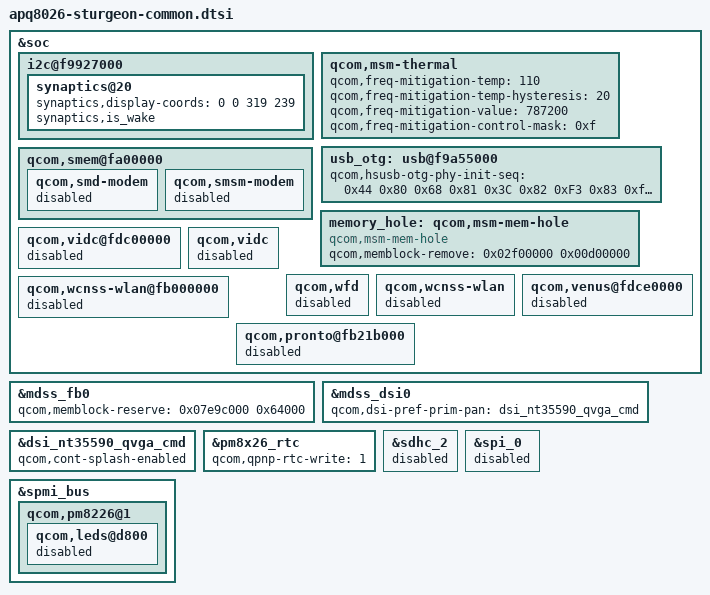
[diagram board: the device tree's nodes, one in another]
/* Copyright (c) 2015, HUAWEI TECHNOLOGIES CO., LTD. All rights reserved.
 *
 * This program is free software; you can redistribute it and/or modify
 * it under the terms of the GNU General Public License version 2 and
 * only version 2 as published by the Free Software Foundation.
 *
 * This program is distributed in the hope that it will be useful,
 * but WITHOUT ANY WARRANTY; without even the implied warranty of
 * MERCHANTABILITY or FITNESS FOR A PARTICULAR PURPOSE.  See the
 * GNU General Public License for more details.
 */

&soc {
	i2c@f9927000 { /* BLSP1 QUP5 */
		synaptics@20 {
			synaptics,display-coords = <0 0 319 239>;
		};
	};

	qcom,msm-thermal {
		qcom,freq-mitigation-temp = <110>;
		qcom,freq-mitigation-temp-hysteresis = <20>;
		qcom,freq-mitigation-value = <787200>;
		qcom,freq-mitigation-control-mask = <0xf>;
	};
	usb_otg: usb@f9a55000 {
		qcom,hsusb-otg-phy-init-seq =
			<0x44 0x80 0x68 0x81 0x3C 0x82 0xF3 0x83 0xffffffff>;
		/delete-property/ qcom,hsusb-otg-disable-reset;
	};
};

&mdss_fb0 {
	/* cont_splash memory*/
	qcom,memblock-reserve = <0x07e9c000 0x64000>;
};

&mdss_dsi0 {
	qcom,dsi-pref-prim-pan = <&dsi_nt35590_qvga_cmd>;
};

&dsi_nt35590_qvga_cmd {
	qcom,cont-splash-enabled;
};

&soc {
	i2c@f9927000 {
		synaptics@20 {
			/delete-property/ synaptics,power-down;
			/delete-property/ synaptics,disable-gpios;
			synaptics,is_wake;
		};
	};
	qcom,smem@fa00000 {
		qcom,smd-modem {
			status = "disabled";
		};
		qcom,smsm-modem {
			status = "disabled";
		};
	};

	memory_hole: qcom,msm-mem-hole {
		compatible = "qcom,msm-mem-hole";
		qcom,memblock-remove = <0x02f00000 0x00d00000>;
	};

	qcom,vidc@fdc00000 {
		status = "disabled";
	};
	qcom,vidc {
		status = "disabled";
	};
	qcom,wfd {
		status = "disabled";
	};
	qcom,wcnss-wlan {
		status = "disabled";
	};
	qcom,wcnss-wlan@fb000000 {
		status = "disabled";
	};
	qcom,venus@fdce0000 {
		status = "disabled";
	};
	qcom,pronto@fb21b000 {
		status = "disabled";
	};
};

&pm8x26_rtc {
	qcom,qpnp-rtc-write = <1>;
};

&sdhc_2 {
	status = "disabled";
};
&spi_0 {
	status = "disabled";
};
&spmi_bus {
       qcom,pm8226@1 {
               qcom,leds@d800 {
                       status = "disabled";
               };
       };
};

